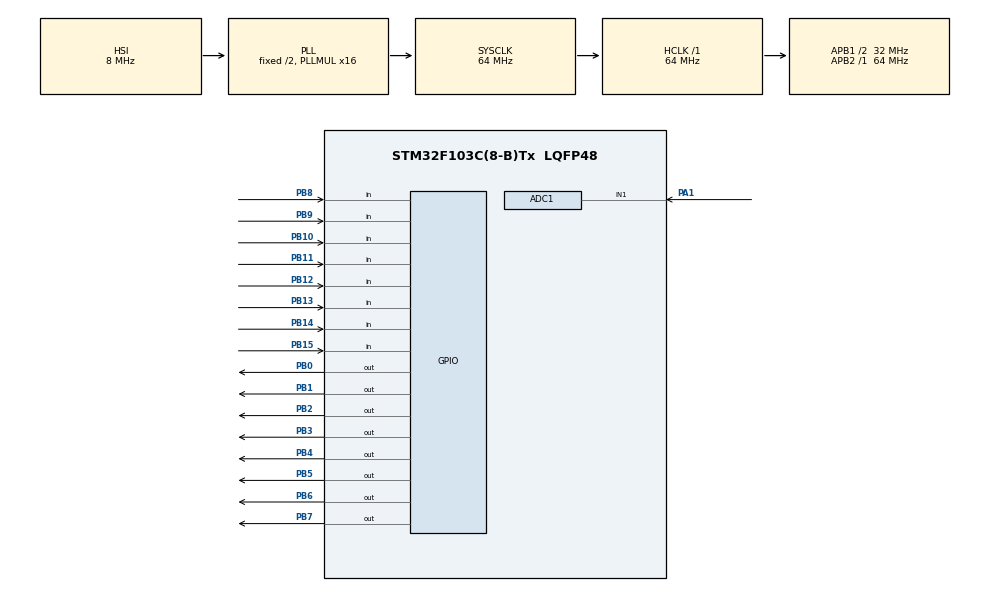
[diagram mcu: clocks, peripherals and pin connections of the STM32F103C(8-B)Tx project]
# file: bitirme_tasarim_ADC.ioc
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ADC1.Channel-0\#ChannelRegularConversion=ADC_CHANNEL_1
ADC1.ExternalTrigConv=ADC_EXTERNALTRIGCONV_T3_TRGO
ADC1.NbrOfConversionFlag=1
ADC1.Rank-0\#ChannelRegularConversion=1
ADC1.SamplingTime-0\#ChannelRegularConversion=ADC_SAMPLETIME_239CYCLES_5
ADC1.master=1
Dma.ADC1.0.Direction=DMA_PERIPH_TO_MEMORY
Dma.ADC1.0.Instance=DMA1_Channel1
Dma.ADC1.0.MemDataAlignment=DMA_MDATAALIGN_HALFWORD
Dma.ADC1.0.MemInc=DMA_MINC_ENABLE
Dma.ADC1.0.Mode=DMA_CIRCULAR
Dma.ADC1.0.PeriphDataAlignment=DMA_PDATAALIGN_HALFWORD
Dma.ADC1.0.PeriphInc=DMA_PINC_DISABLE
Dma.ADC1.0.Priority=DMA_PRIORITY_MEDIUM
Dma.Request0=ADC1
Dma.Request1=TIM3_CH4/UP
Dma.TIM3_CH4/UP.1.Direction=DMA_MEMORY_TO_PERIPH
Dma.TIM3_CH4/UP.1.Instance=DMA1_Channel3
Dma.TIM3_CH4/UP.1.MemDataAlignment=DMA_MDATAALIGN_HALFWORD
Dma.TIM3_CH4/UP.1.MemInc=DMA_MINC_ENABLE
Dma.TIM3_CH4/UP.1.Mode=DMA_CIRCULAR
Dma.TIM3_CH4/UP.1.PeriphDataAlignment=DMA_PDATAALIGN_HALFWORD
Dma.TIM3_CH4/UP.1.PeriphInc=DMA_PINC_DISABLE
Dma.TIM3_CH4/UP.1.Priority=DMA_PRIORITY_LOW
Mcu.Family=STM32F1
Mcu.Name=STM32F103C(8-B)Tx
Mcu.Package=LQFP48
NVIC.DMA1_Channel1_IRQn=true\:0\:0\:false\:false\:true\:false\:true\:true
NVIC.DMA1_Channel3_IRQn=true\:0\:0\:false\:false\:true\:false\:true\:true
NVIC.PriorityGroup=NVIC_PRIORITYGROUP_4
NVIC.TIM3_IRQn=true\:0\:0\:false\:false\:true\:true\:true\:true
PA1.Signal=ADCx_IN1
PA13.Mode=Serial_Wire
PA13.Signal=SYS_JTMS-SWDIO
PA14.Mode=Serial_Wire
PA14.Signal=SYS_JTCK-SWCLK
PB0.Signal=GPIO_Output
PB1.Signal=GPIO_Output
PB10.Signal=GPIO_Input
PB11.Signal=GPIO_Input
PB12.Signal=GPIO_Input
PB13.Signal=GPIO_Input
PB14.Signal=GPIO_Input
PB15.Signal=GPIO_Input
PB2.Signal=GPIO_Output
PB3.Signal=GPIO_Output
PB4.Signal=GPIO_Output
PB5.Signal=GPIO_Output
PB6.Signal=GPIO_Output
PB7.Signal=GPIO_Output
PB8.Signal=GPIO_Input
PB9.Signal=GPIO_Input
ProjectManager.HeapSize=0x200
ProjectManager.StackSize=0x400
ProjectManager.TargetToolchain=STM32CubeIDE
RCC.ADCPresc=RCC_ADCPCLK2_DIV6
RCC.AHBFreq_Value=64000000
RCC.APB1CLKDivider=RCC_HCLK_DIV2
RCC.APB1Freq_Value=32000000
RCC.APB1TimFreq_Value=64000000
RCC.APB2Freq_Value=64000000
RCC.APB2TimFreq_Value=64000000
RCC.HCLKFreq_Value=64000000
RCC.PLLMUL=RCC_PLL_MUL16
RCC.SYSCLKFreq_VALUE=64000000
RCC.SYSCLKSource=RCC_SYSCLKSOURCE_PLLCLK
RCC.USBFreq_Value=64000000
SH.ADCx_IN1.0=ADC1_IN1,IN1
TIM3.Period=999
TIM3.Prescaler=63
TIM3.TIM_MasterOutputTrigger=TIM_TRGO_UPDATE
VP_TIM3_VS_ClockSourceINT.Mode=Internal
board=custom

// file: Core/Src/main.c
/* USER CODE BEGIN Header */
/**
  ******************************************************************************
  * @file           : main.c
  * @brief          : Main program body
  ******************************************************************************
  */
/* USER CODE END Header */
#include "main.h"

/* USER CODE BEGIN Includes */
#include "fir_dsp_driver.h"
/* USER CODE END Includes */

ADC_HandleTypeDef hadc1;
DMA_HandleTypeDef hdma_adc1;

TIM_HandleTypeDef htim3;
DMA_HandleTypeDef hdma_tim3_ch4_up;

void SystemClock_Config(void);
static void MX_GPIO_Init(void);
static void MX_DMA_Init(void);
static void MX_TIM3_Init(void);
static void MX_ADC1_Init(void);

int main(void)
{

  /* MCU Configuration--------------------------------------------------------*/

  /* Reset of all peripherals, Initializes the Flash interface and the Systick. */
  HAL_Init();

  /* Configure the system clock */
  SystemClock_Config();

  /* Initialize all configured peripherals */
  MX_GPIO_Init();
  MX_DMA_Init();
  MX_TIM3_Init();
  MX_ADC1_Init();
  /* USER CODE BEGIN 2 */
  filter_init();

  /* USER CODE END 2 */

  /* Infinite loop */
  while (1)
  {

    /* USER CODE BEGIN 3 */
    filter_process();
  }
  /* USER CODE END 3 */
}

void SystemClock_Config(void)
{
  RCC_OscInitTypeDef RCC_OscInitStruct = {0};
  RCC_ClkInitTypeDef RCC_ClkInitStruct = {0};
  RCC_PeriphCLKInitTypeDef PeriphClkInit = {0};

  /** Initializes the RCC Oscillators according to the specified parameters
  * in the RCC_OscInitTypeDef structure.
  */
  RCC_OscInitStruct.OscillatorType = RCC_OSCILLATORTYPE_HSI;
  RCC_OscInitStruct.HSIState = RCC_HSI_ON;
  RCC_OscInitStruct.HSICalibrationValue = RCC_HSICALIBRATION_DEFAULT;
  RCC_OscInitStruct.PLL.PLLState = RCC_PLL_ON;
  RCC_OscInitStruct.PLL.PLLSource = RCC_PLLSOURCE_HSI_DIV2;
  RCC_OscInitStruct.PLL.PLLMUL = RCC_PLL_MUL16;
  if (HAL_RCC_OscConfig(&RCC_OscInitStruct) != HAL_OK)
  {
    Error_Handler();
  }

  /** Initializes the CPU, AHB and APB buses clocks
  */
  RCC_ClkInitStruct.ClockType = RCC_CLOCKTYPE_HCLK|RCC_CLOCKTYPE_SYSCLK
                              |RCC_CLOCKTYPE_PCLK1|RCC_CLOCKTYPE_PCLK2;
  RCC_ClkInitStruct.SYSCLKSource = RCC_SYSCLKSOURCE_PLLCLK;
  RCC_ClkInitStruct.AHBCLKDivider = RCC_SYSCLK_DIV1;
  RCC_ClkInitStruct.APB1CLKDivider = RCC_HCLK_DIV2;
  RCC_ClkInitStruct.APB2CLKDivider = RCC_HCLK_DIV1;

  if (HAL_RCC_ClockConfig(&RCC_ClkInitStruct, FLASH_LATENCY_2) != HAL_OK)
  {
    Error_Handler();
  }
  PeriphClkInit.PeriphClockSelection = RCC_PERIPHCLK_ADC;
  PeriphClkInit.AdcClockSelection = RCC_ADCPCLK2_DIV6;
  if (HAL_RCCEx_PeriphCLKConfig(&PeriphClkInit) != HAL_OK)
  {
    Error_Handler();
  }
}

static void MX_ADC1_Init(void)
{

  ADC_ChannelConfTypeDef sConfig = {0};

  /** Common config
  */
  hadc1.Instance = ADC1;
  hadc1.Init.ScanConvMode = ADC_SCAN_DISABLE;
  hadc1.Init.ContinuousConvMode = DISABLE;
  hadc1.Init.DiscontinuousConvMode = DISABLE;
  hadc1.Init.ExternalTrigConv = ADC_EXTERNALTRIGCONV_T3_TRGO;
  hadc1.Init.DataAlign = ADC_DATAALIGN_RIGHT;
  hadc1.Init.NbrOfConversion = 1;
  if (HAL_ADC_Init(&hadc1) != HAL_OK)
  {
    Error_Handler();
  }

  /** Configure Regular Channel
  */
  sConfig.Channel = ADC_CHANNEL_1;
  sConfig.Rank = ADC_REGULAR_RANK_1;
  sConfig.SamplingTime = ADC_SAMPLETIME_239CYCLES_5;
  if (HAL_ADC_ConfigChannel(&hadc1, &sConfig) != HAL_OK)
  {
    Error_Handler();
  }

}

static void MX_TIM3_Init(void)
{

  TIM_ClockConfigTypeDef sClockSourceConfig = {0};
  TIM_MasterConfigTypeDef sMasterConfig = {0};

  htim3.Instance = TIM3;
  htim3.Init.Prescaler = 63;
  htim3.Init.CounterMode = TIM_COUNTERMODE_UP;
  htim3.Init.Period = 999;
  htim3.Init.ClockDivision = TIM_CLOCKDIVISION_DIV1;
  htim3.Init.AutoReloadPreload = TIM_AUTORELOAD_PRELOAD_DISABLE;
  if (HAL_TIM_Base_Init(&htim3) != HAL_OK)
  {
    Error_Handler();
  }
  sClockSourceConfig.ClockSource = TIM_CLOCKSOURCE_INTERNAL;
  if (HAL_TIM_ConfigClockSource(&htim3, &sClockSourceConfig) != HAL_OK)
  {
    Error_Handler();
  }
  sMasterConfig.MasterOutputTrigger = TIM_TRGO_UPDATE;
  sMasterConfig.MasterSlaveMode = TIM_MASTERSLAVEMODE_DISABLE;
  if (HAL_TIMEx_MasterConfigSynchronization(&htim3, &sMasterConfig) != HAL_OK)
  {
    Error_Handler();
  }

}

static void MX_DMA_Init(void)
{

  /* DMA controller clock enable */
  __HAL_RCC_DMA1_CLK_ENABLE();

  /* DMA interrupt init */
  /* DMA1_Channel1_IRQn interrupt configuration */
  HAL_NVIC_SetPriority(DMA1_Channel1_IRQn, 0, 0);
  HAL_NVIC_EnableIRQ(DMA1_Channel1_IRQn);
  /* DMA1_Channel3_IRQn interrupt configuration */
  HAL_NVIC_SetPriority(DMA1_Channel3_IRQn, 0, 0);
  HAL_NVIC_EnableIRQ(DMA1_Channel3_IRQn);

}

static void MX_GPIO_Init(void)
{
  GPIO_InitTypeDef GPIO_InitStruct = {0};

  /* GPIO Ports Clock Enable */
  __HAL_RCC_GPIOA_CLK_ENABLE();
  __HAL_RCC_GPIOB_CLK_ENABLE();

  /*Configure GPIO pin Output Level */
  HAL_GPIO_WritePin(GPIOB, GPIO_PIN_0|GPIO_PIN_1|GPIO_PIN_2|GPIO_PIN_3
                          |GPIO_PIN_4|GPIO_PIN_5|GPIO_PIN_6|GPIO_PIN_7, GPIO_PIN_RESET);

  /*Configure GPIO pins : PB0 PB1 PB2 PB3
                           PB4 PB5 PB6 PB7 */
  GPIO_InitStruct.Pin = GPIO_PIN_0|GPIO_PIN_1|GPIO_PIN_2|GPIO_PIN_3
                          |GPIO_PIN_4|GPIO_PIN_5|GPIO_PIN_6|GPIO_PIN_7;
  GPIO_InitStruct.Mode = GPIO_MODE_OUTPUT_PP;
  GPIO_InitStruct.Pull = GPIO_NOPULL;
  GPIO_InitStruct.Speed = GPIO_SPEED_FREQ_LOW;
  HAL_GPIO_Init(GPIOB, &GPIO_InitStruct);

  /*Configure GPIO pins : PB10 PB11 PB12 PB13
                           PB14 PB15 PB8 PB9 */
  GPIO_InitStruct.Pin = GPIO_PIN_10|GPIO_PIN_11|GPIO_PIN_12|GPIO_PIN_13
                          |GPIO_PIN_14|GPIO_PIN_15|GPIO_PIN_8|GPIO_PIN_9;
  GPIO_InitStruct.Mode = GPIO_MODE_INPUT;
  GPIO_InitStruct.Pull = GPIO_NOPULL;
  HAL_GPIO_Init(GPIOB, &GPIO_InitStruct);

}

void Error_Handler(void)
{
  __disable_irq();
  while (1)
  {
  }
}
